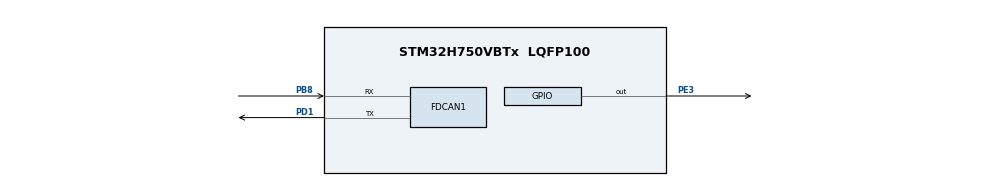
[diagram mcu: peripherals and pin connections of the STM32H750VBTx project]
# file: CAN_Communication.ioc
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CORTEX_M7.default_mode_Activation=1
FDCAN1.CalculateBaudRateNominal=1000000
FDCAN1.CalculateTimeBitNominal=1000
FDCAN1.CalculateTimeQuantumNominal=50.0
FDCAN1.NominalPrescaler=2
FDCAN1.NominalTimeSeg1=16
FDCAN1.NominalTimeSeg2=3
FDCAN1.RxFifo0ElmtsNbr=1
FDCAN1.TxBuffersNbr=1
Mcu.Family=STM32H7
Mcu.Name=STM32H750VBTx
Mcu.Package=LQFP100
NVIC.FDCAN1_IT0_IRQn=true\:0\:0\:false\:false\:true\:true\:true\:true
NVIC.PriorityGroup=NVIC_PRIORITYGROUP_4
PB8.Mode=FDCAN_Activate
PB8.Signal=FDCAN1_RX
PD1.Mode=FDCAN_Activate
PD1.Signal=FDCAN1_TX
PE3.Signal=GPIO_Output
ProjectManager.HeapSize=0x200
ProjectManager.StackSize=0x400
ProjectManager.TargetToolchain=STM32CubeIDE
RCC.ADCFreq_Value=129000000
RCC.APB1Freq_Value=80000000
RCC.APB2Freq_Value=80000000
RCC.APB3Freq_Value=80000000
RCC.APB4Freq_Value=80000000
RCC.CortexFreq_Value=80000000
RCC.DIVM1=4
RCC.DIVN1=10
RCC.DIVQ1=4
RCC.HCLKFreq_Value=80000000
RCC.PLLFRACN=0
RCC.SYSCLKFreq_VALUE=80000000
RCC.SYSCLKSource=RCC_SYSCLKSOURCE_PLLCLK
RCC.USBFreq_Value=40000000
VP_MEMORYMAP_VS_MEMORYMAP.Mode=CurAppReg
board=custom

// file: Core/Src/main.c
/* USER CODE BEGIN Header */
/**
  ******************************************************************************
  * @file           : main.c
  * @brief          : Main program body
  ******************************************************************************
  * @attention
  *
  * Copyright (c) 2025 STMicroelectronics.
  * All rights reserved.
  *
  * This software is licensed under terms that can be found in the LICENSE file
  * in the root directory of this software component.
  * If no LICENSE file comes with this software, it is provided AS-IS.
  *
  ******************************************************************************
  */
/* USER CODE END Header */
#include "main.h"

/* USER CODE BEGIN Includes */
#include <stdio.h>
/* USER CODE END Includes */

FDCAN_HandleTypeDef hfdcan1;

/* USER CODE BEGIN PV */

FDCAN_TxHeaderTypeDef TxHeader;
FDCAN_RxHeaderTypeDef RxHeader;

uint8_t TxData[8];
uint8_t RxData[8];

uint8_t newCanMessage = 0;

static void FDCAN_Config(void)
{
	FDCAN_FilterTypeDef sFilterConfig;

	sFilterConfig.IdType =  FDCAN_STANDARD_ID;
	sFilterConfig.FilterIndex = 0;
	sFilterConfig.FilterType = FDCAN_FILTER_RANGE;
	sFilterConfig.FilterConfig = FDCAN_FILTER_TO_RXFIFO0;
	sFilterConfig.FilterID1 = 0x100;
	sFilterConfig.FilterID2 = 0x200;

	HAL_FDCAN_ConfigFilter(&hfdcan1, &sFilterConfig);

	HAL_FDCAN_ActivateNotification(&hfdcan1, FDCAN_IT_RX_FIFO0_NEW_MESSAGE, 0 );

	if (HAL_FDCAN_Start(&hfdcan1) != HAL_OK){
			Error_Handler();
	}
}

void HAL_FDCAN_RxFifo0Callback(FDCAN_HandleTypeDef *hfdcan, uint32_t RxFifo) //Fogadjuk az üzenetet
	{
	    HAL_FDCAN_GetRxMessage(hfdcan, FDCAN_RX_FIFO0, &RxHeader, RxData);

	    newCanMessage = 1;
	}

/* USER CODE END PV */

void SystemClock_Config(void);
static void MPU_Config(void);
static void MX_GPIO_Init(void);
static void MX_FDCAN1_Init(void);

int main(void)
{

  /* MPU Configuration--------------------------------------------------------*/
  MPU_Config();

  /* MCU Configuration--------------------------------------------------------*/

  /* Reset of all peripherals, Initializes the Flash interface and the Systick. */
  HAL_Init();

  /* Configure the system clock */
  SystemClock_Config();

  /* Initialize all configured peripherals */
  MX_GPIO_Init();
  MX_FDCAN1_Init();
  /* USER CODE BEGIN 2 */

  FDCAN_Config();

  /* USER CODE END 2 */

  /* Infinite loop */
  /* USER CODE BEGIN WHILE */
  while (1)
  {
      TxHeader.Identifier = 0x110;
      TxHeader.IdType = FDCAN_STANDARD_ID;
      TxHeader.TxFrameType = FDCAN_DATA_FRAME;
      TxHeader.DataLength = FDCAN_DLC_BYTES_8;
      TxHeader.ErrorStateIndicator = FDCAN_ESI_ACTIVE;
      TxHeader.BitRateSwitch = FDCAN_BRS_OFF;
      TxHeader.FDFormat = FDCAN_CLASSIC_CAN;
      TxHeader.MessageMarker = 0;
      for(int i = 0; i < 8; i++){
    	  TxData[1] = 0xAB;
      }

      if(HAL_FDCAN_AddMessageToTxFifoQ(&hfdcan1, &TxHeader, TxData) != HAL_OK){
    	  Error_Handler();
      }
    /* USER CODE END WHILE */

  }
}

void SystemClock_Config(void)
{
  RCC_OscInitTypeDef RCC_OscInitStruct = {0};
  RCC_ClkInitTypeDef RCC_ClkInitStruct = {0};

  /** Supply configuration update enable
  */
  HAL_PWREx_ConfigSupply(PWR_LDO_SUPPLY);

  /** Configure the main internal regulator output voltage
  */
  __HAL_PWR_VOLTAGESCALING_CONFIG(PWR_REGULATOR_VOLTAGE_SCALE3);

  while(!__HAL_PWR_GET_FLAG(PWR_FLAG_VOSRDY)) {}

  /** Initializes the RCC Oscillators according to the specified parameters
  * in the RCC_OscInitTypeDef structure.
  */
  RCC_OscInitStruct.OscillatorType = RCC_OSCILLATORTYPE_HSI;
  RCC_OscInitStruct.HSIState = RCC_HSI_DIV1;
  RCC_OscInitStruct.HSICalibrationValue = RCC_HSICALIBRATION_DEFAULT;
  RCC_OscInitStruct.PLL.PLLState = RCC_PLL_ON;
  RCC_OscInitStruct.PLL.PLLSource = RCC_PLLSOURCE_HSI;
  RCC_OscInitStruct.PLL.PLLM = 4;
  RCC_OscInitStruct.PLL.PLLN = 10;
  RCC_OscInitStruct.PLL.PLLP = 2;
  RCC_OscInitStruct.PLL.PLLQ = 4;
  RCC_OscInitStruct.PLL.PLLR = 2;
  RCC_OscInitStruct.PLL.PLLRGE = RCC_PLL1VCIRANGE_3;
  RCC_OscInitStruct.PLL.PLLVCOSEL = RCC_PLL1VCOMEDIUM;
  RCC_OscInitStruct.PLL.PLLFRACN = 0;
  if (HAL_RCC_OscConfig(&RCC_OscInitStruct) != HAL_OK)
  {
    Error_Handler();
  }

  /** Initializes the CPU, AHB and APB buses clocks
  */
  RCC_ClkInitStruct.ClockType = RCC_CLOCKTYPE_HCLK|RCC_CLOCKTYPE_SYSCLK
                              |RCC_CLOCKTYPE_PCLK1|RCC_CLOCKTYPE_PCLK2
                              |RCC_CLOCKTYPE_D3PCLK1|RCC_CLOCKTYPE_D1PCLK1;
  RCC_ClkInitStruct.SYSCLKSource = RCC_SYSCLKSOURCE_PLLCLK;
  RCC_ClkInitStruct.SYSCLKDivider = RCC_SYSCLK_DIV1;
  RCC_ClkInitStruct.AHBCLKDivider = RCC_HCLK_DIV1;
  RCC_ClkInitStruct.APB3CLKDivider = RCC_APB3_DIV1;
  RCC_ClkInitStruct.APB1CLKDivider = RCC_APB1_DIV1;
  RCC_ClkInitStruct.APB2CLKDivider = RCC_APB2_DIV1;
  RCC_ClkInitStruct.APB4CLKDivider = RCC_APB4_DIV1;

  if (HAL_RCC_ClockConfig(&RCC_ClkInitStruct, FLASH_LATENCY_1) != HAL_OK)
  {
    Error_Handler();
  }
}

static void MX_FDCAN1_Init(void)
{

  hfdcan1.Instance = FDCAN1;
  hfdcan1.Init.FrameFormat = FDCAN_FRAME_CLASSIC;
  hfdcan1.Init.Mode = FDCAN_MODE_NORMAL;
  hfdcan1.Init.AutoRetransmission = DISABLE;
  hfdcan1.Init.TransmitPause = DISABLE;
  hfdcan1.Init.ProtocolException = DISABLE;
  hfdcan1.Init.NominalPrescaler = 2;
  hfdcan1.Init.NominalSyncJumpWidth = 1;
  hfdcan1.Init.NominalTimeSeg1 = 16;
  hfdcan1.Init.NominalTimeSeg2 = 3;
  hfdcan1.Init.DataPrescaler = 1;
  hfdcan1.Init.DataSyncJumpWidth = 1;
  hfdcan1.Init.DataTimeSeg1 = 1;
  hfdcan1.Init.DataTimeSeg2 = 1;
  hfdcan1.Init.MessageRAMOffset = 0;
  hfdcan1.Init.StdFiltersNbr = 0;
  hfdcan1.Init.ExtFiltersNbr = 0;
  hfdcan1.Init.RxFifo0ElmtsNbr = 1;
  hfdcan1.Init.RxFifo0ElmtSize = FDCAN_DATA_BYTES_8;
  hfdcan1.Init.RxFifo1ElmtsNbr = 0;
  hfdcan1.Init.RxFifo1ElmtSize = FDCAN_DATA_BYTES_8;
  hfdcan1.Init.RxBuffersNbr = 0;
  hfdcan1.Init.RxBufferSize = FDCAN_DATA_BYTES_8;
  hfdcan1.Init.TxEventsNbr = 0;
  hfdcan1.Init.TxBuffersNbr = 1;
  hfdcan1.Init.TxFifoQueueElmtsNbr = 0;
  hfdcan1.Init.TxFifoQueueMode = FDCAN_TX_FIFO_OPERATION;
  hfdcan1.Init.TxElmtSize = FDCAN_DATA_BYTES_8;
  if (HAL_FDCAN_Init(&hfdcan1) != HAL_OK)
  {
    Error_Handler();
  }

}

static void MX_GPIO_Init(void)
{
  GPIO_InitTypeDef GPIO_InitStruct = {0};

  /* GPIO Ports Clock Enable */
  __HAL_RCC_GPIOE_CLK_ENABLE();
  __HAL_RCC_GPIOD_CLK_ENABLE();
  __HAL_RCC_GPIOB_CLK_ENABLE();

  /*Configure GPIO pin Output Level */
  HAL_GPIO_WritePin(GPIOE, GPIO_PIN_3, GPIO_PIN_RESET);

  /*Configure GPIO pin : PE3 */
  GPIO_InitStruct.Pin = GPIO_PIN_3;
  GPIO_InitStruct.Mode = GPIO_MODE_OUTPUT_PP;
  GPIO_InitStruct.Pull = GPIO_NOPULL;
  GPIO_InitStruct.Speed = GPIO_SPEED_FREQ_LOW;
  HAL_GPIO_Init(GPIOE, &GPIO_InitStruct);

}

 /* MPU Configuration */

void MPU_Config(void)
{
  MPU_Region_InitTypeDef MPU_InitStruct = {0};

  /* Disables the MPU */
  HAL_MPU_Disable();

  /** Initializes and configures the Region and the memory to be protected
  */
  MPU_InitStruct.Enable = MPU_REGION_ENABLE;
  MPU_InitStruct.Number = MPU_REGION_NUMBER0;
  MPU_InitStruct.BaseAddress = 0x0;
  MPU_InitStruct.Size = MPU_REGION_SIZE_4GB;
  MPU_InitStruct.SubRegionDisable = 0x87;
  MPU_InitStruct.TypeExtField = MPU_TEX_LEVEL0;
  MPU_InitStruct.AccessPermission = MPU_REGION_NO_ACCESS;
  MPU_InitStruct.DisableExec = MPU_INSTRUCTION_ACCESS_DISABLE;
  MPU_InitStruct.IsShareable = MPU_ACCESS_SHAREABLE;
  MPU_InitStruct.IsCacheable = MPU_ACCESS_NOT_CACHEABLE;
  MPU_InitStruct.IsBufferable = MPU_ACCESS_NOT_BUFFERABLE;

  HAL_MPU_ConfigRegion(&MPU_InitStruct);
  /* Enables the MPU */
  HAL_MPU_Enable(MPU_PRIVILEGED_DEFAULT);

}

void Error_Handler(void)
{
  /* USER CODE BEGIN Error_Handler_Debug */
  /* User can add his own implementation to report the HAL error return state */
  while (1)
  {
	  HAL_GPIO_WritePin(GPIOE, GPIO_PIN_3, 1);
	  HAL_Delay(100);
	  HAL_GPIO_WritePin(GPIOE, GPIO_PIN_3, 0);
	  HAL_Delay(100);
  }
  /* USER CODE END Error_Handler_Debug */
}
